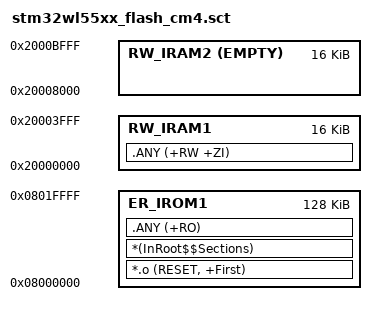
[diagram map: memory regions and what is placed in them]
; *************************************************************
; *** Scatter-Loading Description File generated by uVision ***
; *************************************************************

LR_IROM1 0x08000000 0x00020000  {    ; load region size_region
  ; FLASH part dedicated to M4
  ER_IROM1 0x08000000 0x00020000  {  ; load address = execution address
   *.o (RESET, +First)
   *(InRoot$$Sections)
   .ANY (+RO)
  }
  ; Non-backup SRAM1 dedicated to M4
  RW_IRAM1 0x20000000 0x00004000  {  ; RW data
   .ANY (+RW +ZI)
  }
  ; Backup SRAM2 dedicated to M4
  RW_IRAM2 0x20008000 EMPTY 0x00004000  {  ; to be modified accordingly to user project. Can be NoInit data for backup usage, RW, ZI region, etc...
  }
}
